CM_ "IMPORT _community.dbc";
CM_ "IMPORT _honda_common.dbc";
CM_ "IMPORT _dual_nidec_common.dbc";
CM_ "IMPORT _steering_sensors_b.dbc";

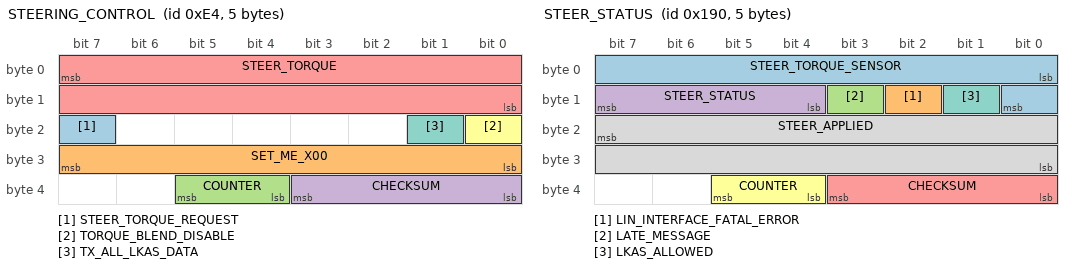
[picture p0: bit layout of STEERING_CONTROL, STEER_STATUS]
BO_ 228 STEERING_CONTROL: 5 ADAS
 SG_ STEER_TORQUE_REQUEST : 23|1@0+ (1,0) [0|1] "" EPS
 SG_ SET_ME_X00 : 31|8@0+ (1,0) [0|0] "" EPS
 SG_ COUNTER : 37|2@0+ (1,0) [0|3] "" EPS
 SG_ CHECKSUM : 35|4@0+ (1,0) [0|3] "" EPS
 SG_ STEER_TORQUE : 7|16@0- (1,0) [-3840|3840] "" EPS
 SG_ TORQUE_BLEND_DISABLE : 16|1@0+ (1,0) [0|1] "" XXX
 SG_ TX_ALL_LKAS_DATA : 17|1@0+ (1,0) [0|1] "" XXX

BO_ 400 STEER_STATUS: 5 EPS
 SG_ STEER_TORQUE_SENSOR : 0|9@1- (1,0) [-256|256] "" XXX
 SG_ LIN_INTERFACE_FATAL_ERROR : 10|1@0+ (1,0) [0|1] "" XXX
 SG_ LATE_MESSAGE : 11|1@0+ (1,0) [0|1] "" XXX
 SG_ STEER_STATUS : 12|4@1+ (1,0) [0|15] "" XXX
 SG_ CHECKSUM : 35|4@0+ (1,0) [0|3] "" EON
 SG_ COUNTER : 37|2@0+ (1,0) [0|3] "" XXX
 SG_ LKAS_ALLOWED : 9|1@0+ (1,0) [0|1] "" XXX
 SG_ STEER_APPLIED : 23|16@0- (1,0) [0|511] "" XXX

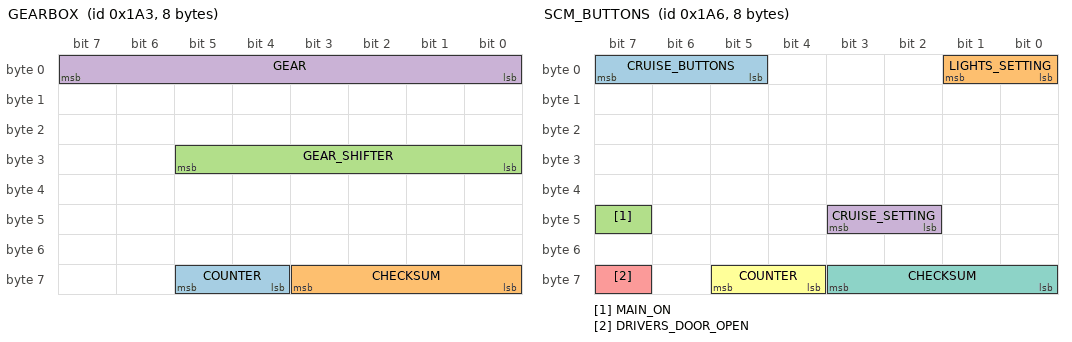
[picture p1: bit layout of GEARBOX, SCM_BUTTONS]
BO_ 419 GEARBOX: 8 PCM
 SG_ COUNTER : 61|2@0+ (1,0) [0|3] "" EON
 SG_ CHECKSUM : 59|4@0+ (1,0) [0|3] "" EON
 SG_ GEAR_SHIFTER : 29|6@0+ (1,0) [0|63] "" EON
 SG_ GEAR : 7|8@0+ (1,0) [0|255] "" EON

BO_ 422 SCM_BUTTONS: 8 SCM
 SG_ CRUISE_BUTTONS : 7|3@0+ (1,0) [0|7] "" EON
 SG_ LIGHTS_SETTING : 1|2@0+ (1,0) [0|3] "" EON
 SG_ MAIN_ON : 47|1@0+ (1,0) [0|1] "" EON
 SG_ CRUISE_SETTING : 43|2@0+ (1,0) [0|3] "" EON
 SG_ DRIVERS_DOOR_OPEN : 63|1@0+ (1,0) [0|1] "" EON
 SG_ COUNTER : 61|2@0+ (1,0) [0|3] "" EON
 SG_ CHECKSUM : 59|4@0+ (1,0) [0|3] "" EON

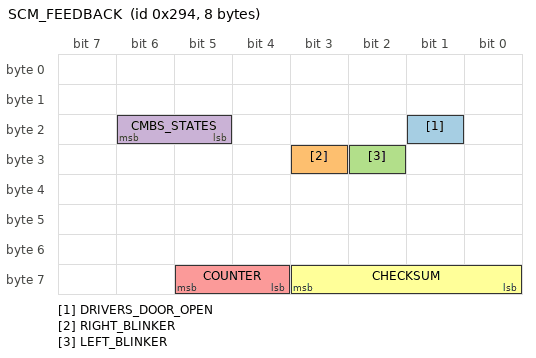
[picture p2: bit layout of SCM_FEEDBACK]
BO_ 660 SCM_FEEDBACK: 8 SCM
 SG_ DRIVERS_DOOR_OPEN : 17|1@0+ (1,0) [0|1] "" XXX
 SG_ RIGHT_BLINKER : 27|1@0+ (1,0) [0|1] "" EON
 SG_ LEFT_BLINKER : 26|1@0+ (1,0) [0|1] "" EON
 SG_ CMBS_STATES : 22|2@0+ (1,0) [0|3] "" EON
 SG_ COUNTER : 61|2@0+ (1,0) [0|3] "" XXX
 SG_ CHECKSUM : 59|4@0+ (1,0) [0|15] "" XXX

CM_ SG_ 422 PARKING_BRAKE_LIGHT "Believe this is just the dash light for the parking break";
VAL_ 400 STEER_STATUS 6 "tmp_fault" 5 "fault_1" 4 "no_torque_alert_2" 3 "low_speed_lockout" 2 "no_torque_alert_1" 0 "normal" ;
VAL_ 419 GEAR_SHIFTER 32 "D" 8 "R" 4 "P" ;
VAL_ 422 CRUISE_BUTTONS 7 "tbd" 6 "tbd" 5 "tbd" 4 "accel_res" 3 "decel_set" 2 "cancel" 1 "main" 0 "none" ;
